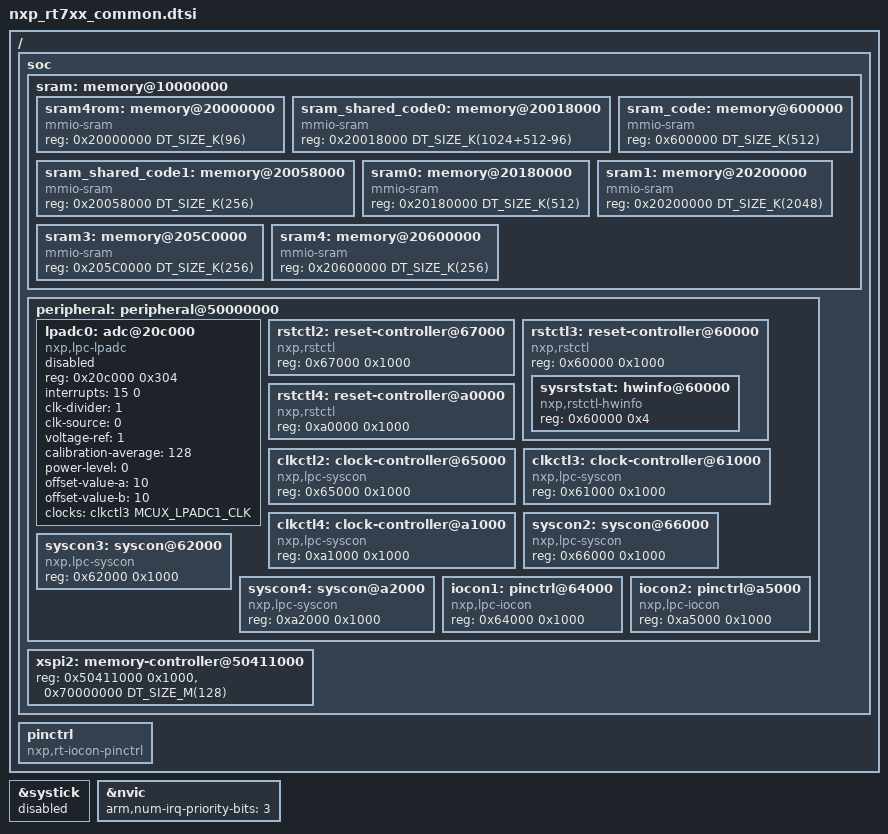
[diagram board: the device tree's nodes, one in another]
/*
 * Copyright 2025 NXP
 *
 * SPDX-License-Identifier: Apache-2.0
 */

#include <mem.h>
#include <freq.h>
#include <arm/armv8-m.dtsi>
#include <zephyr/dt-bindings/adc/adc.h>
#include <zephyr/dt-bindings/clock/mcux_lpc_syscon_clock.h>
#include <zephyr/dt-bindings/gpio/gpio.h>
#include <zephyr/dt-bindings/memory-attr/memory-attr-arm.h>
#include <zephyr/dt-bindings/reset/nxp_syscon_reset_common.h>

/ {
	soc {
		sram: memory@10000000 {
			ranges = <0x0 0x10000000 0x780000
			0x20000000 0x30000000 0x780000>;
		};

		peripheral: peripheral@50000000 {
			ranges = <0x0 0x50000000 0x10000000>;
		};

		xspi2: memory-controller@50411000 {
			reg = <0x50411000 0x1000>, <0x70000000 DT_SIZE_M(128)>;
		};
	};

	pinctrl: pinctrl {
		compatible = "nxp,rt-iocon-pinctrl";
	};
};

&sram {
	#address-cells = <1>;
	#size-cells = <1>;

	/* RT7XX SRAM partitions are shared between code and data. Boards can
	 *  override the reg properties of either sram0 or sram_code nodes to
	 *  change the balance of SRAM allocation.
	 *
	 * The SRAM region [0x000000-0x017FFF] is reserved for ROM bootloader execution.
	 * Can be reused after boot.
	 * The SRAM region [0x018000-0x17FFFF] is reserved for Non-cached shared memory
	 * or application data.
	 * The SRAM region [0x180000-0x1FFFFF] is reserved for CPU0 application, last
	 * 2MB non-cacheable data for NPU/GPU/Display etc.
	 * The SRAM region [0x200000-0x400000] is reserved for HiFi4 application.
	 *
	 * The SRAM region [0x580000-0x5BFFFF] is reserved for shared memory or application data.
	 * The SRAM region [0x5C0000-0x67FFFF] is reserved for CPU1 application.
	 * The SRAM region [0x680000-0x77FFFF] is reserved for HiFi1 application.
	 */

	sram4rom: memory@20000000 {
		compatible = "mmio-sram";
		reg = <0x20000000 DT_SIZE_K(96)>;
	};

	/* This partition is shared with code in RAM */
	sram_shared_code0: memory@20018000 {
		compatible = "mmio-sram";
		reg = <0x20018000 DT_SIZE_K(1024+512-96)>;
	};

	sram_code: memory@600000 {
		compatible = "mmio-sram";
		reg = <0x600000 DT_SIZE_K(512)>;
	};

	/* This partition is shared with code in RAM */
	sram_shared_code1: memory@20058000 {
		compatible = "mmio-sram";
		reg = <0x20058000 DT_SIZE_K(256)>;
	};

	sram0: memory@20180000 {
		compatible = "mmio-sram";
		reg = <0x20180000 DT_SIZE_K(512)>;
	};

	sram1: memory@20200000 {
		compatible = "mmio-sram";
		reg = <0x20200000 DT_SIZE_K(2048)>;
	};

	sram3: memory@205C0000 {
		compatible = "mmio-sram";
		/* Only use 256K, align with SDK */
		reg = <0x205C0000 DT_SIZE_K(256)>;
	};

	sram4: memory@20600000 {
		compatible = "mmio-sram";
		reg = <0x20600000 DT_SIZE_K(256)>;
	};
};

&peripheral {
	#address-cells = <1>;
	#size-cells = <1>;
	/*
	 * Note that the offsets here are relative to the base address.
	 * The base addresses differ between non-secure (0x40000000)
	 * and secure modes (0x50000000).
	 */

	lpadc0: adc@20c000 {
		compatible = "nxp,lpc-lpadc";
		reg = <0x20c000 0x304>;
		interrupts = <15 0>;
		status = "disabled";
		clk-divider = <1>;
		clk-source = <0>;
		voltage-ref = <1>;
		calibration-average = <128>;
		power-level = <0>;
		offset-value-a = <10>;
		offset-value-b = <10>;
		#io-channel-cells = <1>;
		clocks = <&clkctl3 MCUX_LPADC1_CLK>;
	};

	rstctl2: reset-controller@67000 {
		compatible = "nxp,rstctl";
		reg = <0x67000 0x1000>;
		#reset-cells = <1>;
	};

	rstctl3: reset-controller@60000 {
		compatible = "nxp,rstctl";
		reg = <0x60000 0x1000>;
		#reset-cells = <1>;
		#address-cells = <1>;
		#size-cells = <1>;

		sysrststat: hwinfo@60000 {
			compatible = "nxp,rstctl-hwinfo";
			reg = <0x60000 0x4>;
		};
	};

	rstctl4: reset-controller@a0000 {
		compatible = "nxp,rstctl";
		reg = <0xa0000 0x1000>;
		#reset-cells = <1>;
	};

	clkctl2: clock-controller@65000 {
		compatible = "nxp,lpc-syscon";
		reg = <0x65000 0x1000>;
		#clock-cells = <1>;
	};

	clkctl3: clock-controller@61000 {
		compatible = "nxp,lpc-syscon";
		reg = <0x61000 0x1000>;
		#clock-cells = <1>;
	};

	clkctl4: clock-controller@a1000 {
		compatible = "nxp,lpc-syscon";
		reg = <0xa1000 0x1000>;
		#clock-cells = <1>;
	};

	syscon2: syscon@66000 {
		compatible = "nxp,lpc-syscon";
		reg = <0x66000 0x1000>;
		#clock-cells = <1>;
	};

	syscon3: syscon@62000 {
		compatible = "nxp,lpc-syscon";
		reg = <0x62000 0x1000>;
		#clock-cells = <1>;
	};

	syscon4: syscon@a2000 {
		compatible = "nxp,lpc-syscon";
		reg = <0xa2000 0x1000>;
		#clock-cells = <1>;
	};

	iocon1: pinctrl@64000 {
		compatible = "nxp,lpc-iocon";
		reg = <0x64000 0x1000>;
		status = "okay";
	};

	iocon2: pinctrl@a5000 {
		compatible = "nxp,lpc-iocon";
		reg = <0xa5000 0x1000>;
		status = "okay";
	};
};

&systick {
	/*
	 * RT700 cm33 cores relies by default on the OS Timer for system
	 * clock implementation, so the SysTick node is not to be enabled.
	 */
	status = "disabled";
};

&nvic {
	arm,num-irq-priority-bits = <3>;
};
